CM_ "AUTOGENERATED FILE, DO NOT EDIT"

CM_ "Imported file _bosch_2018.dbc starts here"
VERSION ""

NS_ :

BU_: EBCM EON CAM RADAR PCM EPS VSA SCM BDY XXX EPB

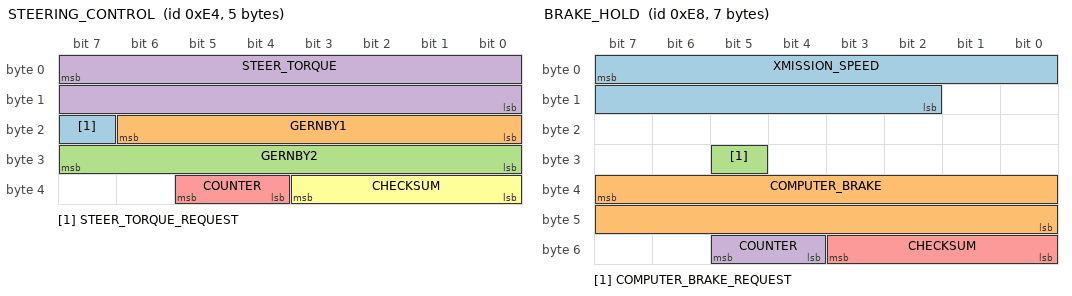
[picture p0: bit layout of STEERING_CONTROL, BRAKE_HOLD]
BO_ 228 STEERING_CONTROL: 5 XXX
 SG_ STEER_TORQUE_REQUEST : 23|1@0+ (1,0) [0|1] "" EPS
 SG_ GERNBY1 : 22|7@0+ (1,0) [0|127] "" EPS
 SG_ GERNBY2 : 31|8@0+ (1,0) [0|0] "" EPS
 SG_ STEER_TORQUE : 7|16@0- (1,0) [-4096|4096] "" EPS
 SG_ COUNTER : 37|2@0+ (1,0) [0|3] "" EPS
 SG_ CHECKSUM : 35|4@0+ (1,0) [0|15] "" EPS

BO_ 232 BRAKE_HOLD: 7 XXX
 SG_ XMISSION_SPEED : 7|14@0- (1,0) [1|0] "" XXX
 SG_ COMPUTER_BRAKE : 39|16@0+ (1,0) [0|0] "" XXX
 SG_ COMPUTER_BRAKE_REQUEST : 29|1@0+ (1,0) [0|0] "" XXX
 SG_ COUNTER : 53|2@0+ (1,0) [0|3] "" XXX
 SG_ CHECKSUM : 51|4@0+ (1,0) [0|15] "" XXX

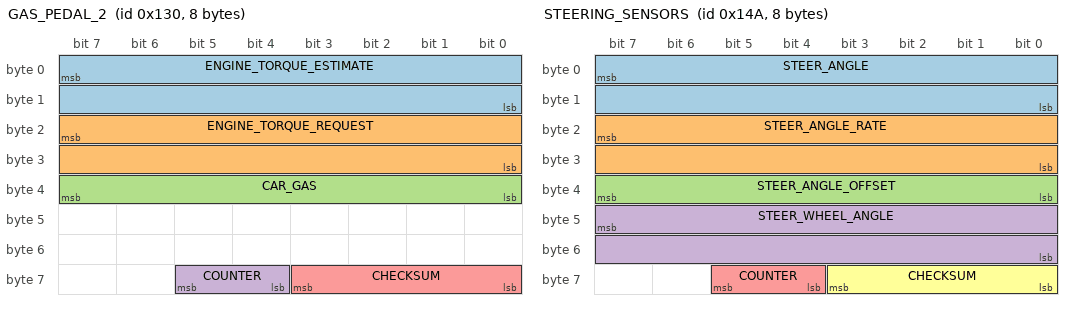
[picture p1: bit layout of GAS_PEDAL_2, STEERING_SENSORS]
BO_ 304 GAS_PEDAL_2: 8 PCM
 SG_ ENGINE_TORQUE_ESTIMATE : 7|16@0- (1,0) [-1000|1000] "Nm" EON
 SG_ ENGINE_TORQUE_REQUEST : 23|16@0- (1,0) [-1000|1000] "Nm" EON
 SG_ CAR_GAS : 39|8@0+ (1,0) [0|255] "" EON
 SG_ COUNTER : 61|2@0+ (1,0) [0|3] "" EON
 SG_ CHECKSUM : 59|4@0+ (1,0) [0|15] "" EON

BO_ 330 STEERING_SENSORS: 8 EPS
 SG_ STEER_ANGLE : 7|16@0- (-0.1,0) [-500|500] "deg" EON
 SG_ STEER_ANGLE_RATE : 23|16@0- (-1,0) [-3000|3000] "deg/s" EON
 SG_ STEER_ANGLE_OFFSET : 39|8@0- (-0.1,0) [-128|127] "deg" EON
 SG_ STEER_WHEEL_ANGLE : 47|16@0- (-0.1,0) [-500|500] "deg" EON
 SG_ COUNTER : 61|2@0+ (1,0) [0|3] "" EON
 SG_ CHECKSUM : 59|4@0+ (1,0) [0|15] "" EON

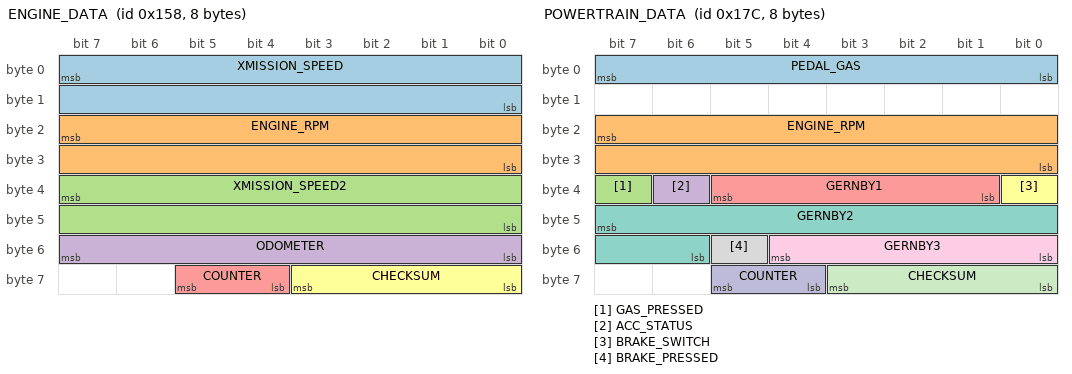
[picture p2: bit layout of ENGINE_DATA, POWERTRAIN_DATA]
BO_ 344 ENGINE_DATA: 8 PCM
 SG_ XMISSION_SPEED : 7|16@0+ (0.01,0) [0|250] "kph" EON
 SG_ ENGINE_RPM : 23|16@0+ (1,0) [0|15000] "rpm" EON
 SG_ XMISSION_SPEED2 : 39|16@0+ (0.01,0) [0|250] "kph" EON
 SG_ ODOMETER : 55|8@0+ (10,0) [0|2550] "m" XXX
 SG_ COUNTER : 61|2@0+ (1,0) [0|3] "" EON
 SG_ CHECKSUM : 59|4@0+ (1,0) [0|15] "" EON

BO_ 380 POWERTRAIN_DATA: 8 PCM
 SG_ PEDAL_GAS : 7|8@0+ (1,0) [0|255] "" EON
 SG_ ENGINE_RPM : 23|16@0+ (1,0) [0|15000] "rpm" EON
 SG_ GAS_PRESSED : 39|1@0+ (1,0) [0|1] "" EON
 SG_ ACC_STATUS : 38|1@0+ (1,0) [0|1] "" EON
 SG_ GERNBY1 : 37|5@0+ (1,0) [0|1] "" EON
 SG_ BRAKE_SWITCH : 32|1@0+ (1,0) [0|1] "" EON
 SG_ GERNBY2 : 47|10@0+ (1,0) [0|1] "" EON
 SG_ BRAKE_PRESSED : 53|1@0+ (1,0) [0|1] "" EON
 SG_ GERNBY3 : 52|5@0+ (1,0) [0|1] "" EON
 SG_ COUNTER : 61|2@0+ (1,0) [0|3] "" EON
 SG_ CHECKSUM : 59|4@0+ (1,0) [0|15] "" EON

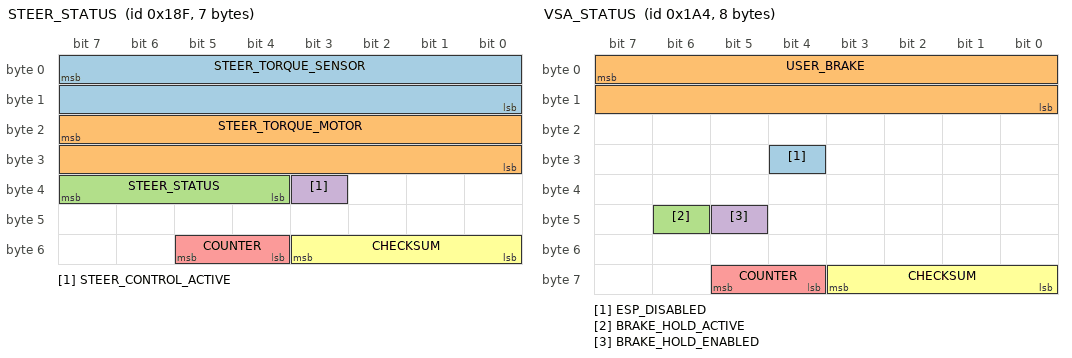
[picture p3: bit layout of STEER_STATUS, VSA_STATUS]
BO_ 399 STEER_STATUS: 7 EPS
 SG_ STEER_TORQUE_SENSOR : 7|16@0- (1,0) [-31000|31000] "tbd" EON
 SG_ STEER_TORQUE_MOTOR : 23|16@0- (1,0) [-31000|31000] "tbd" EON
 SG_ STEER_STATUS : 39|4@0+ (1,0) [0|15] "" EON
 SG_ STEER_CONTROL_ACTIVE : 35|1@0+ (1,0) [0|1] "" EON
 SG_ COUNTER : 53|2@0+ (1,0) [0|3] "" EON
 SG_ CHECKSUM : 51|4@0+ (1,0) [0|15] "" EON

BO_ 420 VSA_STATUS: 8 VSA
 SG_ ESP_DISABLED : 28|1@0+ (1,0) [0|1] "" EON
 SG_ USER_BRAKE : 7|16@0+ (0.015625,-1.609375) [0|1000] "" EON
 SG_ BRAKE_HOLD_ACTIVE : 46|1@0+ (1,0) [0|1] "" EON
 SG_ BRAKE_HOLD_ENABLED : 45|1@0+ (1,0) [0|1] "" EON
 SG_ COUNTER : 61|2@0+ (1,0) [0|3] "" EON
 SG_ CHECKSUM : 59|4@0+ (1,0) [0|15] "" EON

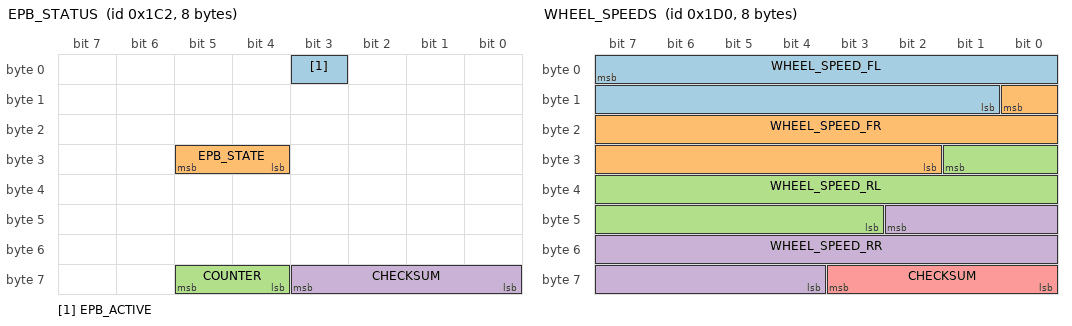
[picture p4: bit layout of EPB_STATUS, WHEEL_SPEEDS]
BO_ 450 EPB_STATUS: 8 EPB
 SG_ EPB_ACTIVE : 3|1@0+ (1,0) [0|1] "" EON
 SG_ EPB_STATE : 29|2@0+ (1,0) [0|3] "" EON
 SG_ COUNTER : 61|2@0+ (1,0) [0|3] "" XXX
 SG_ CHECKSUM : 59|4@0+ (1,0) [0|15] "" XXX

BO_ 464 WHEEL_SPEEDS: 8 VSA
 SG_ WHEEL_SPEED_FL : 7|15@0+ (0.01,0) [0|250] "kph" EON
 SG_ WHEEL_SPEED_FR : 8|15@0+ (0.01,0) [0|250] "kph" EON
 SG_ WHEEL_SPEED_RL : 25|15@0+ (0.01,0) [0|250] "kph" EON
 SG_ WHEEL_SPEED_RR : 42|15@0+ (0.01,0) [0|250] "kph" EON
 SG_ CHECKSUM : 59|4@0+ (1,0) [0|3] "" EON

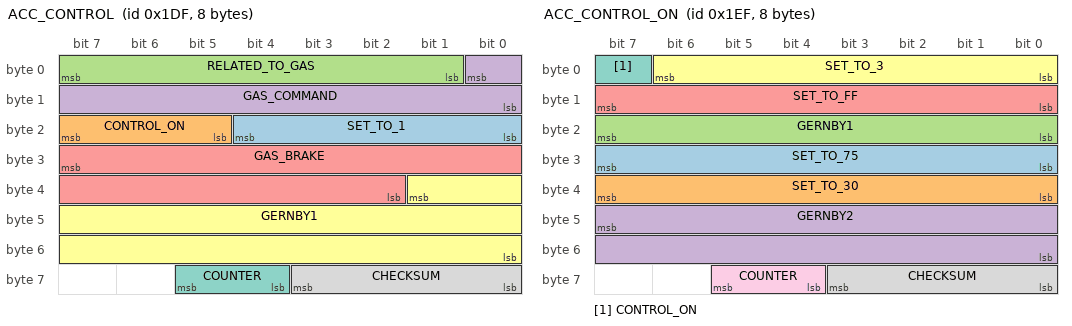
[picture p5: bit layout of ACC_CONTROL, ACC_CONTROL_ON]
BO_ 479 ACC_CONTROL: 8 EON
 SG_ SET_TO_1 : 20|5@0+ (1,0) [0|1] "" PCM
 SG_ CONTROL_ON : 23|3@0+ (1,0) [0|5] "" XXX
 SG_ RELATED_TO_GAS : 7|7@0+ (1,0) [0|69] "" XXX
 SG_ GAS_COMMAND : 0|9@0+ (1,0) [0|1] "" PCM
 SG_ GAS_BRAKE : 31|14@0- (1,0) [0|1] "" XXX
 SG_ GERNBY1 : 33|18@0+ (1,0) [100|100] "" XXX
 SG_ COUNTER : 61|2@0+ (1,0) [0|3] "" XXX
 SG_ CHECKSUM : 59|4@0+ (1,0) [0|15] "" XXX

BO_ 495 ACC_CONTROL_ON: 8 XXX
 SG_ SET_TO_75 : 31|8@0+ (1,0) [0|255] "" XXX
 SG_ SET_TO_30 : 39|8@0+ (1,0) [0|255] "" XXX
 SG_ GERNBY1 : 23|8@0+ (1,0) [0|255] "" XXX
 SG_ GERNBY2 : 47|16@0+ (1,0) [0|255] "" XXX
 SG_ SET_TO_FF : 15|8@0+ (1,0) [0|255] "" XXX
 SG_ SET_TO_3 : 6|7@0+ (1,0) [0|4095] "" XXX
 SG_ CONTROL_ON : 7|1@0+ (1,0) [0|1] "" XXX
 SG_ CHECKSUM : 59|4@0+ (1,0) [0|15] "" XXX
 SG_ COUNTER : 61|2@0+ (1,0) [0|3] "" XXX

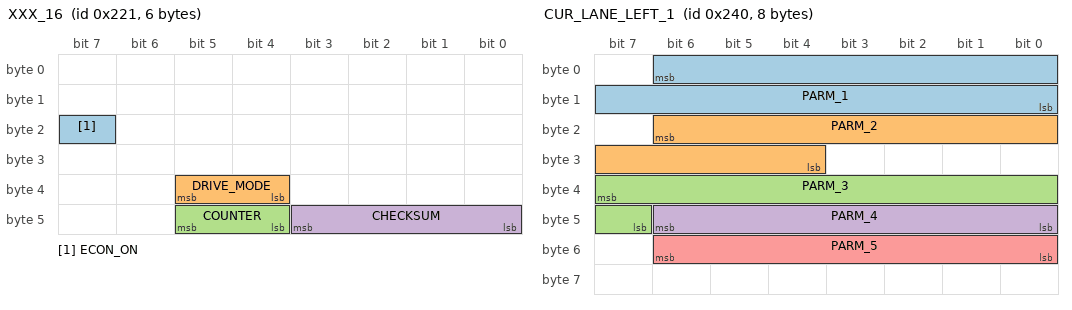
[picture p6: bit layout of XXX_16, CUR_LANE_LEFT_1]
BO_ 545 XXX_16: 6 SCM
 SG_ ECON_ON : 23|1@0+ (1,0) [0|1] "" XXX
 SG_ DRIVE_MODE : 37|2@0+ (1,0) [0|3] "" XXX
 SG_ COUNTER : 45|2@0+ (1,0) [0|3] "" BDY
 SG_ CHECKSUM : 43|4@0+ (1,0) [0|15] "" BDY

BO_ 576 CUR_LANE_LEFT_1: 8 XXX
 SG_ PARM_1 : 6|15@0- (1,0) [-16384|16384] "" XXX
 SG_ PARM_2 : 22|11@0- (1,0) [-1023|1023] "" XXX
 SG_ PARM_3 : 39|9@0+ (1,0) [0|511] "" XXX
 SG_ PARM_4 : 46|7@0+ (1,0) [0|127] "" XXX
 SG_ PARM_5 : 54|7@0+ (1,0) [0|127] "" XXX

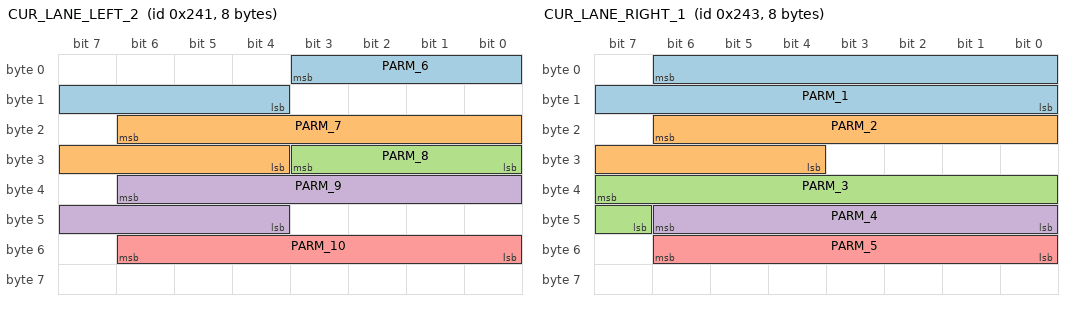
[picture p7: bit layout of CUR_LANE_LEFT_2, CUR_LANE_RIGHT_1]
BO_ 577 CUR_LANE_LEFT_2: 8 XXX
 SG_ PARM_6 : 3|8@0+ (1,0) [0|255] "" XXX
 SG_ PARM_7 : 22|11@0- (1,0) [-1023|1023] "" XXX
 SG_ PARM_8 : 24|4@1+ (1,0) [0|15] "" XXX
 SG_ PARM_9 : 38|11@0- (1,0) [-1023|1023] "" XXX
 SG_ PARM_10 : 54|7@0- (1,0) [-63|63] "" XXX

BO_ 579 CUR_LANE_RIGHT_1: 8 XXX
 SG_ PARM_1 : 6|15@0- (1,0) [-16384|16384] "" XXX
 SG_ PARM_2 : 22|11@0- (1,0) [-1023|1023] "" XXX
 SG_ PARM_3 : 39|9@0+ (1,0) [0|511] "" XXX
 SG_ PARM_4 : 46|7@0+ (1,0) [0|127] "" XXX
 SG_ PARM_5 : 54|7@0+ (1,0) [0|127] "" XXX

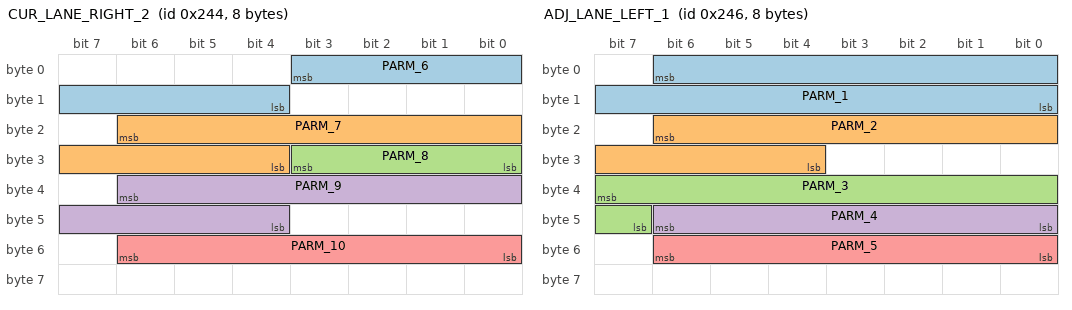
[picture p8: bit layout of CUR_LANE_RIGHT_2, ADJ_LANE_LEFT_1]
BO_ 580 CUR_LANE_RIGHT_2: 8 XXX
 SG_ PARM_6 : 3|8@0+ (1,0) [0|255] "" XXX
 SG_ PARM_7 : 22|11@0- (1,0) [-1023|1023] "" XXX
 SG_ PARM_8 : 24|4@1+ (1,0) [0|15] "" XXX
 SG_ PARM_9 : 38|11@0- (1,0) [-1023|1023] "" XXX
 SG_ PARM_10 : 54|7@0- (1,0) [-63|63] "" XXX

BO_ 582 ADJ_LANE_LEFT_1: 8 XXX
 SG_ PARM_1 : 6|15@0- (1,0) [-16384|16384] "" XXX
 SG_ PARM_2 : 22|11@0- (1,0) [-1023|1023] "" XXX
 SG_ PARM_3 : 39|9@0+ (1,0) [0|511] "" XXX
 SG_ PARM_4 : 46|7@0+ (1,0) [0|127] "" XXX
 SG_ PARM_5 : 54|7@0+ (1,0) [0|127] "" XXX

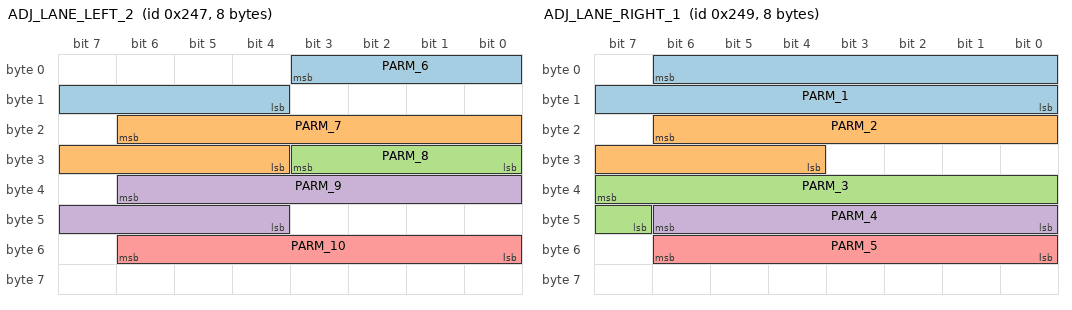
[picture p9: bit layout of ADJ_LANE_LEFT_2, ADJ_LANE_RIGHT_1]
BO_ 583 ADJ_LANE_LEFT_2: 8 XXX
 SG_ PARM_6 : 3|8@0+ (1,0) [0|255] "" XXX
 SG_ PARM_7 : 22|11@0- (1,0) [-1023|1023] "" XXX
 SG_ PARM_8 : 24|4@1+ (1,0) [0|15] "" XXX
 SG_ PARM_9 : 38|11@0- (1,0) [-1023|1023] "" XXX
 SG_ PARM_10 : 54|7@0- (1,0) [-63|63] "" XXX

BO_ 585 ADJ_LANE_RIGHT_1: 8 XXX
 SG_ PARM_1 : 6|15@0- (1,0) [-16384|16384] "" XXX
 SG_ PARM_2 : 22|11@0- (1,0) [-1023|1023] "" XXX
 SG_ PARM_3 : 39|9@0+ (1,0) [0|511] "" XXX
 SG_ PARM_4 : 46|7@0+ (1,0) [0|127] "" XXX
 SG_ PARM_5 : 54|7@0+ (1,0) [0|127] "" XXX

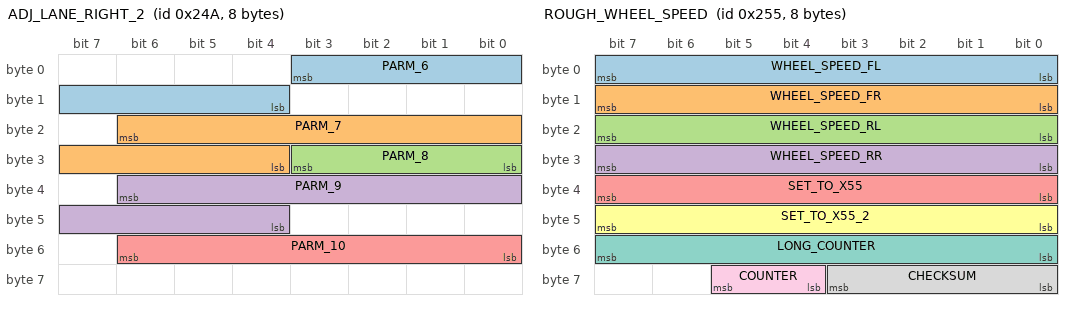
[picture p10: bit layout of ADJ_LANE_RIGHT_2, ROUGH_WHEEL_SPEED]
BO_ 586 ADJ_LANE_RIGHT_2: 8 XXX
 SG_ PARM_6 : 3|8@0+ (1,0) [0|255] "" XXX
 SG_ PARM_7 : 22|11@0- (1,0) [-1023|1023] "" XXX
 SG_ PARM_8 : 24|4@1+ (1,0) [0|15] "" XXX
 SG_ PARM_9 : 38|11@0- (1,0) [-1023|1023] "" XXX
 SG_ PARM_10 : 54|7@0- (1,0) [-63|63] "" XXX

BO_ 597 ROUGH_WHEEL_SPEED: 8 VSA
 SG_ WHEEL_SPEED_FL : 7|8@0+ (1,0) [0|255] "mph" EON
 SG_ WHEEL_SPEED_FR : 15|8@0+ (1,0) [0|255] "mph" EON
 SG_ WHEEL_SPEED_RL : 23|8@0+ (1,0) [0|255] "mph" EON
 SG_ WHEEL_SPEED_RR : 31|8@0+ (1,0) [0|255] "mph" EON
 SG_ SET_TO_X55 : 39|8@0+ (1,0) [0|255] "" XXX
 SG_ SET_TO_X55_2 : 47|8@0+ (1,0) [0|255] "" EON
 SG_ LONG_COUNTER : 55|8@0+ (1,0) [0|255] "" XXX
 SG_ CHECKSUM : 59|4@0+ (1,0) [0|15] "" XXX
 SG_ COUNTER : 61|2@0+ (1,0) [0|3] "" XXX

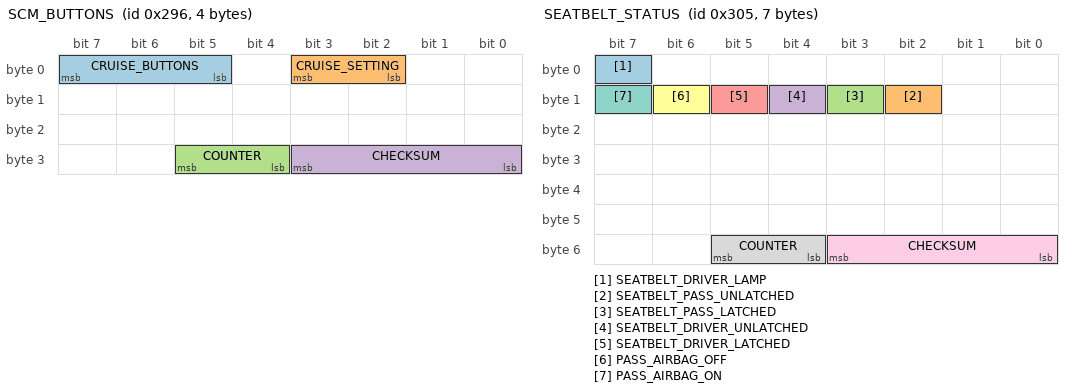
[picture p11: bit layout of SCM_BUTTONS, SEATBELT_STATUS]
BO_ 662 SCM_BUTTONS: 4 SCM
 SG_ CRUISE_BUTTONS : 7|3@0+ (1,0) [0|7] "" EON
 SG_ CRUISE_SETTING : 3|2@0+ (1,0) [0|3] "" EON
 SG_ COUNTER : 29|2@0+ (1,0) [0|3] "" EON
 SG_ CHECKSUM : 27|4@0+ (1,0) [0|15] "" EON

BO_ 773 SEATBELT_STATUS: 7 BDY
 SG_ SEATBELT_DRIVER_LAMP : 7|1@0+ (1,0) [0|1] "" EON
 SG_ SEATBELT_PASS_UNLATCHED : 10|1@0+ (1,0) [0|1] "" EON
 SG_ SEATBELT_PASS_LATCHED : 11|1@0+ (1,0) [0|1] "" EON
 SG_ SEATBELT_DRIVER_UNLATCHED : 12|1@0+ (1,0) [0|1] "" EON
 SG_ SEATBELT_DRIVER_LATCHED : 13|1@0+ (1,0) [0|1] "" EON
 SG_ PASS_AIRBAG_OFF : 14|1@0+ (1,0) [0|1] "" EON
 SG_ PASS_AIRBAG_ON : 15|1@0+ (1,0) [0|1] "" EON
 SG_ COUNTER : 53|2@0+ (1,0) [0|3] "" EON
 SG_ CHECKSUM : 51|4@0+ (1,0) [0|3] "" EON

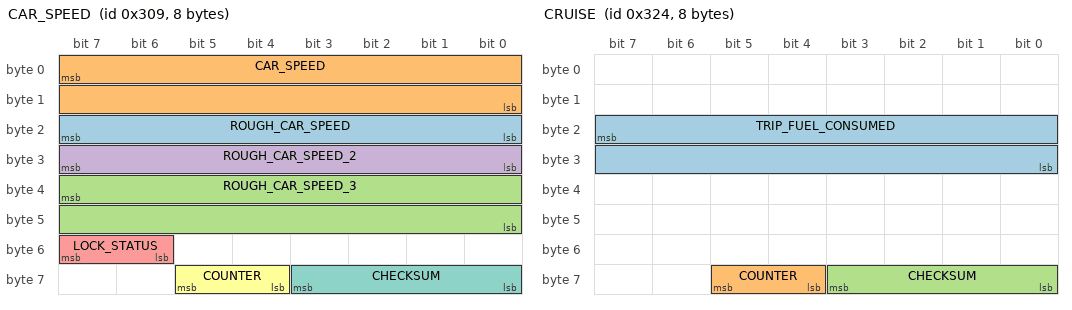
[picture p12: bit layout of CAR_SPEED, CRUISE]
BO_ 777 CAR_SPEED: 8 PCM
 SG_ ROUGH_CAR_SPEED : 23|8@0+ (1,0) [0|255] "" XXX
 SG_ CAR_SPEED : 7|16@0+ (1,0) [0|65535] "" XXX
 SG_ ROUGH_CAR_SPEED_3 : 39|16@0+ (1,0) [0|65535] "" XXX
 SG_ ROUGH_CAR_SPEED_2 : 31|8@0+ (1,0) [0|255] "" XXX
 SG_ LOCK_STATUS : 55|2@0+ (1,0) [0|255] "" XXX
 SG_ COUNTER : 61|2@0+ (1,0) [0|3] "" XXX
 SG_ CHECKSUM : 59|4@0+ (1,0) [0|15] "" XXX

BO_ 780 ACC_HUD: 8 ADAS
 SG_ CRUISE_SPEED : 31|8@0+ (1,0) [0|255] "" BDY
 SG_ DTC_MODE : 39|1@0+ (1,0) [0|1] "" BDY
 SG_ GERNBY1 : 38|1@0+ (1,0) [0|1] "" BDY
 SG_ FCM_PROBLEM : 34|1@0+ (1,0) [0|1] "" BDY
 SG_ RADAR_OBSTRUCTED : 33|1@0+ (1,0) [0|1] "" BDY
 SG_ ENABLE_MINI_CAR : 32|1@0+ (1,0) [0|1] "" BDY
 SG_ GERNBY2 : 43|1@0+ (1,0) [0|3] "" BDY
 SG_ GERNBY3 : 42|1@0+ (1,0) [0|3] "" BDY
 SG_ GERNBY4 : 41|1@0+ (1,0) [0|3] "" BDY
 SG_ CRUISE_CONTROL_LABEL : 40|1@0+ (1,0) [0|3] "" BDY
 SG_ GERNBY5 : 7|24@0+ (0.002759506,0) [0|100] "m/s" BDY
 SG_ FCM_OFF : 35|1@0+ (1,0) [0|1] "" BDY
 SG_ SET_TO_1 : 36|1@0+ (1,0) [0|1] "" XXX
 SG_ HUD_DISTANCE : 47|2@0+ (1,0) [0|3] "" BDY
 SG_ HUD_LEAD : 45|2@0+ (1,0) [0|3] "" BDY
 SG_ ACC_PROBLEM : 37|1@0+ (1,0) [0|1] "" BDY
 SG_ ACC_ON : 52|1@0+ (1,0) [0|1] "" XXX
 SG_ GERNBY7 : 51|4@0+ (1,0) [0|15] "" XXX
 SG_ SET_TO_X3 : 55|2@0+ (1,0) [0|3] "" XXX
 SG_ COUNTER : 61|2@0+ (1,0) [0|3] "" XXX
 SG_ CHECKSUM : 59|4@0+ (1,0) [0|15] "" XXX

BO_ 804 CRUISE: 8 PCM
 SG_ TRIP_FUEL_CONSUMED : 23|16@0+ (1,0) [0|255] "" EON
 SG_ COUNTER : 61|2@0+ (1,0) [0|3] "" EON
 SG_ CHECKSUM : 59|4@0+ (1,0) [0|15] "" EON

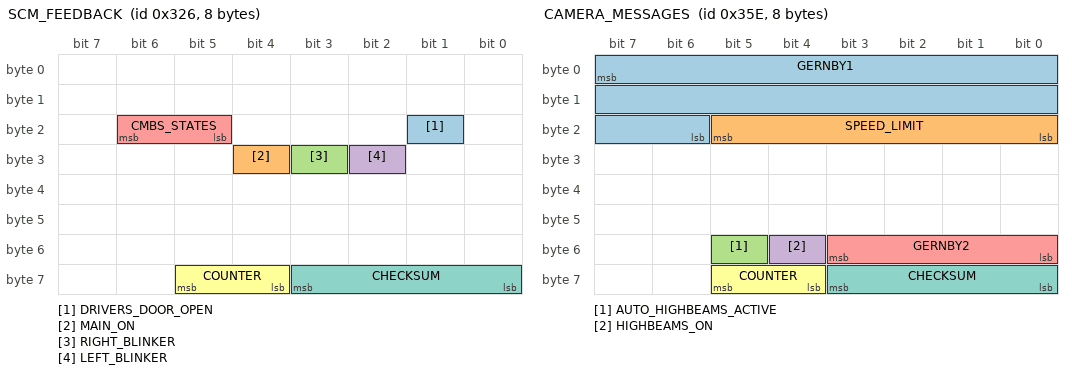
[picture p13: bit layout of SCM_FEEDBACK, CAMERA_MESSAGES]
BO_ 806 SCM_FEEDBACK: 8 SCM
 SG_ DRIVERS_DOOR_OPEN : 17|1@0+ (1,0) [0|1] "" XXX
 SG_ MAIN_ON : 28|1@0+ (1,0) [0|1] "" EON
 SG_ RIGHT_BLINKER : 27|1@0+ (1,0) [0|1] "" EON
 SG_ LEFT_BLINKER : 26|1@0+ (1,0) [0|1] "" EON
 SG_ CMBS_STATES : 22|2@0+ (1,0) [0|3] "" EON
 SG_ COUNTER : 61|2@0+ (1,0) [0|3] "" XXX
 SG_ CHECKSUM : 59|4@0+ (1,0) [0|15] "" XXX

BO_ 829 LKAS_HUD: 5 ADAS
 SG_ CAM_TEMP_HIGH : 7|1@0+ (1,0) [0|1] "" BDY
 SG_ GERNBY3 : 6|7@0+ (1,0) [0|127] "" BDY
 SG_ GERNBY1 : 6|7@0+ (1,0) [0|127] "" BDY
 SG_ DASHED_LANES : 14|1@0+ (1,0) [0|1] "" BDY
 SG_ DTC : 13|1@0+ (1,0) [0|1] "" BDY
 SG_ LKAS_PROBLEM : 12|1@0+ (1,0) [0|1] "" BDY
 SG_ LKAS_OFF : 11|1@0+ (1,0) [0|1] "" BDY
 SG_ SOLID_LANES : 10|1@0+ (1,0) [0|1] "" BDY
 SG_ LDW_RIGHT : 9|1@0+ (1,0) [0|1] "" BDY
 SG_ STEERING_REQUIRED : 8|1@0+ (1,0) [0|1] "" BDY
 SG_ GERNBY2 : 23|2@0+ (1,0) [0|3] "" BDY
 SG_ LDW_PROBLEM : 21|1@0+ (1,0) [0|1] "" BDY
 SG_ BEEP : 17|2@0+ (1,0) [0|1] "" BDY
 SG_ LDW_ON : 28|1@0+ (1,0) [0|1] "" BDY
 SG_ LDW_OFF : 27|1@0+ (1,0) [0|1] "" BDY
 SG_ CLEAN_WINDSHIELD : 26|1@0+ (1,0) [0|1] "" BDY
 SG_ GERNBY4 : 31|8@0+ (1,0) [0|255] "" BDY
 SG_ COUNTER : 37|2@0+ (1,0) [0|3] "" BDY
 SG_ CHECKSUM : 35|4@0+ (1,0) [0|15] "" BDY

BO_ 862 CAMERA_MESSAGES: 8 CAM
 SG_ GERNBY1 : 7|18@0+ (1,0) [0|127] "" BDY
 SG_ SPEED_LIMIT : 21|6@0- (8.05,0) [0|31] "" XXX
 SG_ AUTO_HIGHBEAMS_ACTIVE : 53|1@0+ (1,0) [0|1] "" XXX
 SG_ HIGHBEAMS_ON : 52|1@0+ (1,0) [0|1] "" XXX
 SG_ GERNBY2 : 51|4@0+ (1,0) [0|15] "" XXX
 SG_ COUNTER : 61|2@0+ (1,0) [0|3] "" XXX
 SG_ CHECKSUM : 59|4@0+ (1,0) [0|15] "" XXX

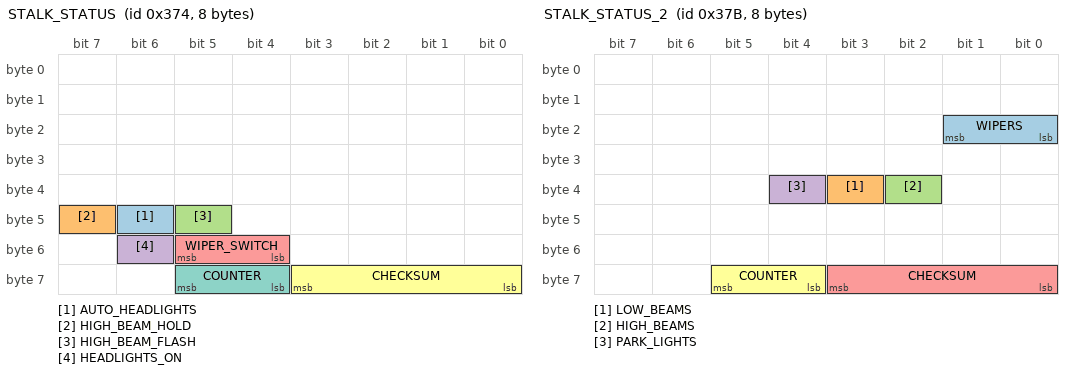
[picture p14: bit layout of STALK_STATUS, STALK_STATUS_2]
BO_ 884 STALK_STATUS: 8 XXX
 SG_ AUTO_HEADLIGHTS : 46|1@0+ (1,0) [0|1] "" EON
 SG_ HIGH_BEAM_HOLD : 47|1@0+ (1,0) [0|1] "" EON
 SG_ HIGH_BEAM_FLASH : 45|1@0+ (1,0) [0|1] "" EON
 SG_ HEADLIGHTS_ON : 54|1@0+ (1,0) [0|1] "" EON
 SG_ WIPER_SWITCH : 53|2@0+ (1,0) [0|3] "" XXX
 SG_ CHECKSUM : 59|4@0+ (1,0) [0|3] "" EON
 SG_ COUNTER : 61|2@0+ (1,0) [0|3] "" EON

BO_ 891 STALK_STATUS_2: 8 XXX
 SG_ WIPERS : 17|2@0+ (1,0) [0|3] "" EON
 SG_ LOW_BEAMS : 35|1@0+ (1,0) [0|1] "" XXX
 SG_ HIGH_BEAMS : 34|1@0+ (1,0) [0|1] "" XXX
 SG_ PARK_LIGHTS : 36|1@0+ (1,0) [0|1] "" XXX
 SG_ CHECKSUM : 59|4@0+ (1,0) [0|3] "" EON
 SG_ COUNTER : 61|2@0+ (1,0) [0|3] "" EON

CM_ "honda_accord_s2t_2018_can.dbc starts here"

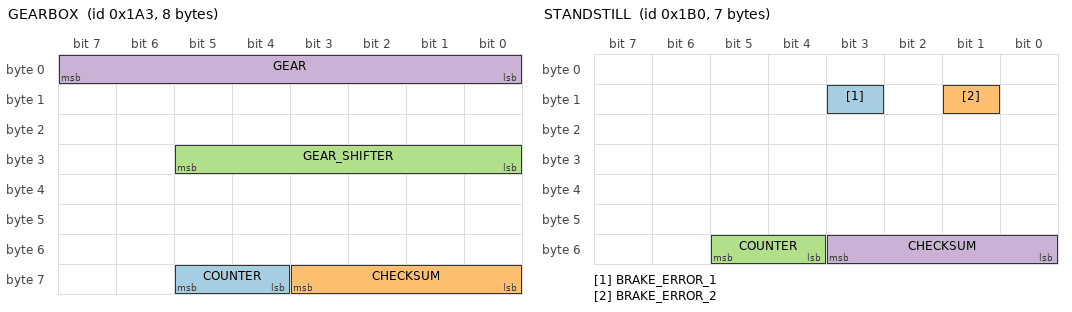
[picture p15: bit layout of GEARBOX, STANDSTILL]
BO_ 419 GEARBOX: 8 PCM
 SG_ COUNTER : 61|2@0+ (1,0) [0|3] "" EON
 SG_ CHECKSUM : 59|4@0+ (1,0) [0|3] "" EON
 SG_ GEAR_SHIFTER : 29|6@0+ (1,0) [0|63] "" EON
 SG_ GEAR : 7|8@0+ (1,0) [0|255] "" EON

BO_ 432 STANDSTILL: 7 VSA
 SG_ BRAKE_ERROR_1 : 11|1@0+ (1,0) [0|1] "" EON
 SG_ BRAKE_ERROR_2 : 9|1@0+ (1,0) [0|1] "" EON
 SG_ COUNTER : 53|2@0+ (1,0) [0|3] "" EON
 SG_ CHECKSUM : 51|4@0+ (1,0) [0|15] "" EON

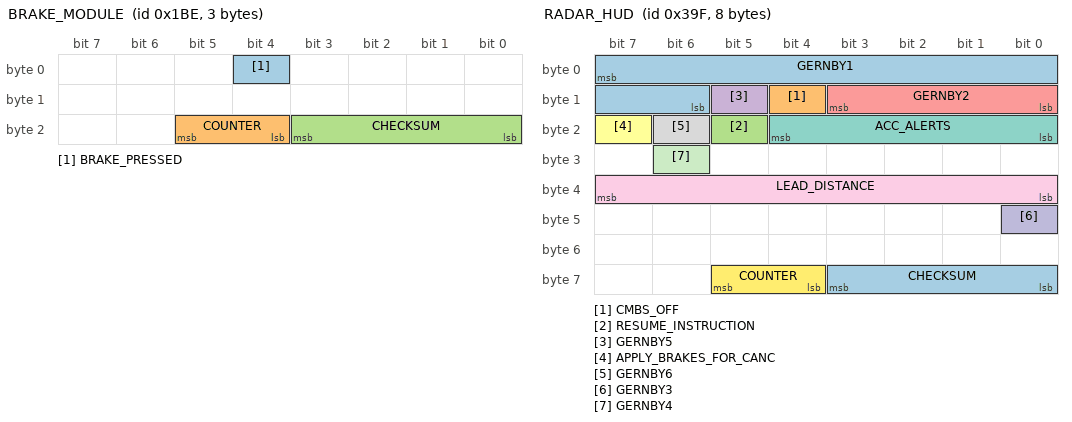
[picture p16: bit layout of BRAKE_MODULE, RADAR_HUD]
BO_ 446 BRAKE_MODULE: 3 VSA
 SG_ BRAKE_PRESSED : 4|1@0+ (1,0) [0|1] "" XXX
 SG_ COUNTER : 21|2@0+ (1,0) [0|3] "" XXX
 SG_ CHECKSUM : 19|4@0+ (1,0) [0|15] "" XXX

BO_ 927 RADAR_HUD: 8 RADAR
 SG_ GERNBY1 : 7|10@0+ (1,0) [0|1023] "" BDY
 SG_ CMBS_OFF : 12|1@0+ (1,0) [0|1] "" BDY
 SG_ RESUME_INSTRUCTION : 21|1@0+ (1,0) [0|1] "" XXX
 SG_ GERNBY5 : 13|1@0+ (1,0) [0|1] "" BDY
 SG_ GERNBY2 : 11|4@0+ (1,0) [0|15] "" XXX
 SG_ APPLY_BRAKES_FOR_CANC : 23|1@0+ (1,0) [0|1] "" XXX
 SG_ ACC_ALERTS : 20|5@0+ (1,0) [0|31] "" BDY
 SG_ GERNBY6 : 22|1@0+ (1,0) [0|1] "" XXX
 SG_ LEAD_DISTANCE : 39|8@0+ (1,0) [0|255] "" XXX
 SG_ GERNBY3 : 40|1@0+ (1,0) [0|1] "" XXX
 SG_ GERNBY4 : 30|1@0+ (1,0) [0|1] "" XXX
 SG_ COUNTER : 61|2@0+ (1,0) [0|3] "" XXX
 SG_ CHECKSUM : 59|4@0+ (1,0) [0|15] "" XXX

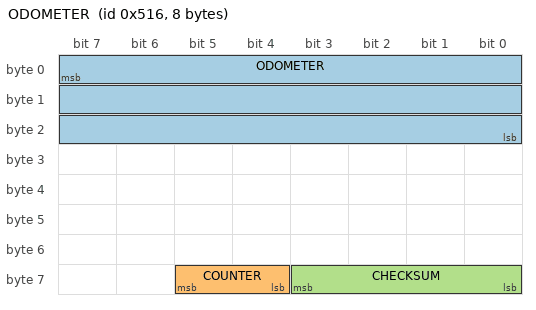
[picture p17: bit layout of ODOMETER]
BO_ 1302 ODOMETER: 8 XXX
 SG_ ODOMETER : 7|24@0+ (1,0) [0|16777215] "km" EON
 SG_ COUNTER : 61|2@0+ (1,0) [0|3] "" EON
 SG_ CHECKSUM : 59|4@0+ (1,0) [0|3] "" EON

VAL_ 419 GEAR_SHIFTER  32 "D" 8 "R" 4 "P" ;
VAL_ 545 ECON_ON_2 0 "off" 3 "on" ;
VAL_ 662 CRUISE_BUTTONS 7 "tbd" 6 "tbd" 5 "tbd" 4 "accel_res" 3 "decel_set" 2 "cancel" 1 "main" 0 "none" ;
VAL_ 662 CRUISE_SETTING 3 "distance_adj" 2 "tbd" 1 "lkas_button" 0 "none" ;
VAL_ 806 CMBS_BUTTON 3 "pressed" 0 "released" ;
VAL_ 891 WIPERS 4 "High" 2 "Low" 0 "Off" ;
VAL_ 829 BEEP 3 "single_beep" 2 "triple_beep" 1 "repeated_beep" 0 "no_beep" ;

CM_ "CHFFR_METRIC 330 STEER_ANGLE STEER_ANGLE 0.36 180; CHFFR_METRIC 380 ENGINE_RPM ENGINE_RPM 1 0; CHFFR_METRIC 804 ENGINE_TEMPERATURE ENGINE_TEMPERATURE 1 0";
